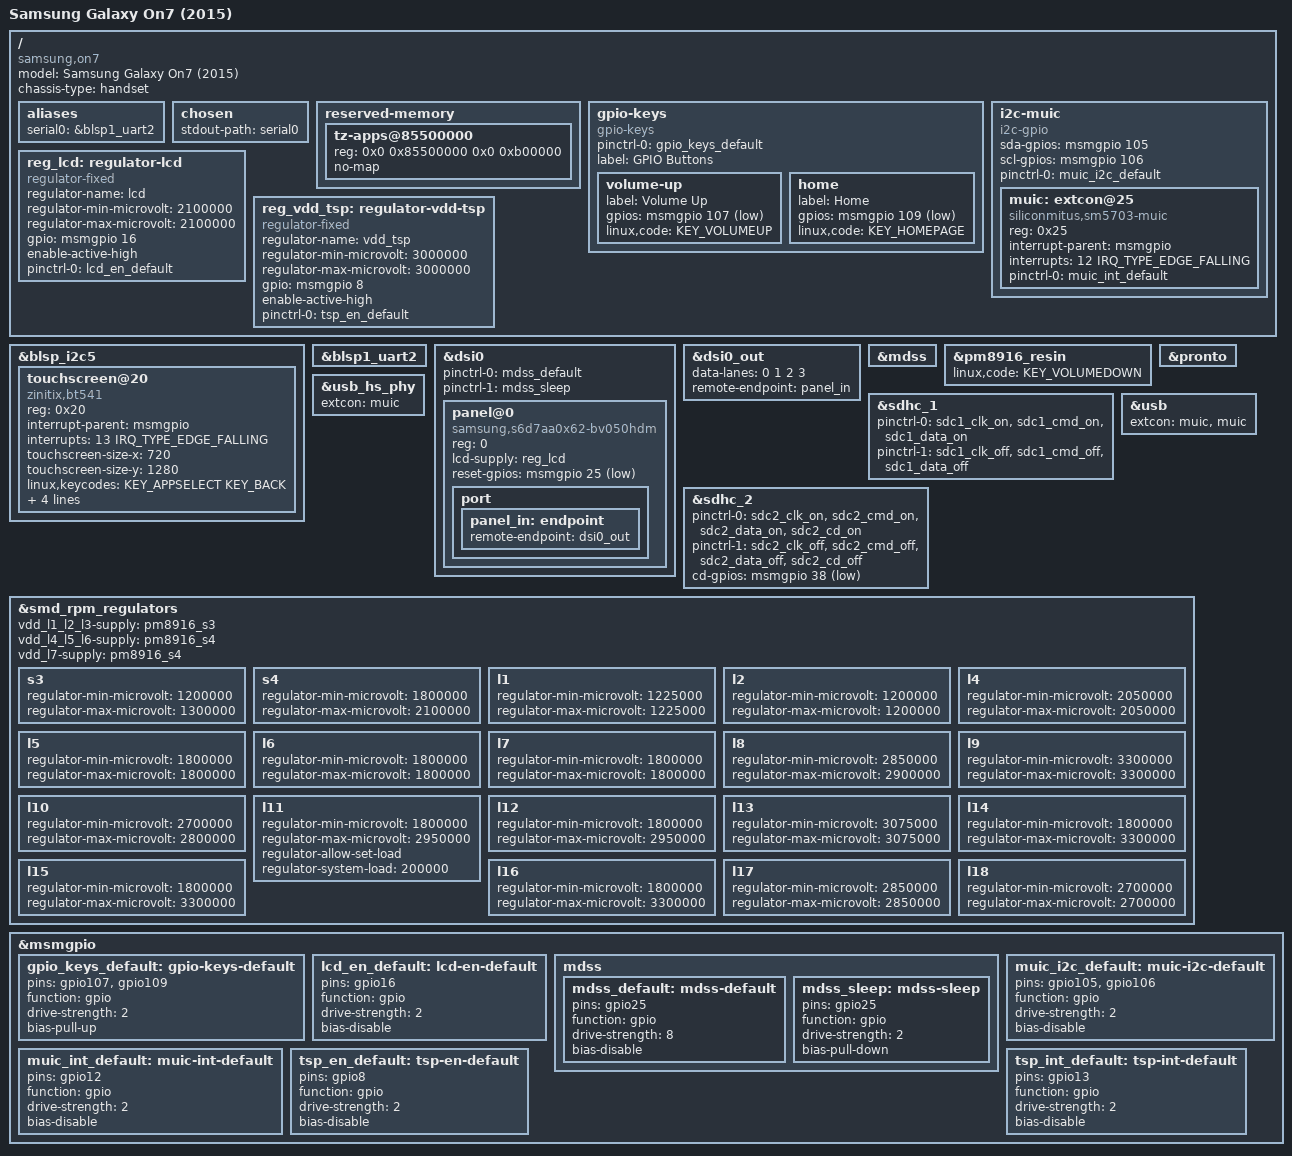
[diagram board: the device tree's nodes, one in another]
// SPDX-License-Identifier: GPL-2.0-only

/dts-v1/;

#include "msm8916-pm8916.dtsi"
#include <dt-bindings/gpio/gpio.h>
#include <dt-bindings/interrupt-controller/irq.h>

/ {
	model = "Samsung Galaxy On7 (2015)";
	compatible = "samsung,on7", "qcom,msm8916";
	chassis-type = "handset";

	aliases {
		serial0 = &blsp1_uart2;
	};

	chosen {
		stdout-path = "serial0";
	};

	reserved-memory {
		/* Additional memory used by Samsung firmware modifications */
		tz-apps@85500000 {
			reg = <0x0 0x85500000 0x0 0xb00000>;
			no-map;
		};
	};

	gpio-keys {
		compatible = "gpio-keys";

		pinctrl-names = "default";
		pinctrl-0 = <&gpio_keys_default>;

		label = "GPIO Buttons";

		volume-up {
			label = "Volume Up";
			gpios = <&msmgpio 107 GPIO_ACTIVE_LOW>;
			linux,code = <KEY_VOLUMEUP>;
		};

		home {
			label = "Home";
			gpios = <&msmgpio 109 GPIO_ACTIVE_LOW>;
			linux,code = <KEY_HOMEPAGE>;
		};
	};

	i2c-muic {
		compatible = "i2c-gpio";
		sda-gpios = <&msmgpio 105 (GPIO_ACTIVE_HIGH|GPIO_OPEN_DRAIN)>;
		scl-gpios = <&msmgpio 106 (GPIO_ACTIVE_HIGH|GPIO_OPEN_DRAIN)>;

		pinctrl-names = "default";
		pinctrl-0 = <&muic_i2c_default>;

		#address-cells = <1>;
		#size-cells = <0>;

		muic: extcon@25 {
			compatible = "siliconmitus,sm5703-muic";
			reg = <0x25>;

			interrupt-parent = <&msmgpio>;
			interrupts = <12 IRQ_TYPE_EDGE_FALLING>;

			pinctrl-names = "default";
			pinctrl-0 = <&muic_int_default>;
		};
	};

	reg_lcd: regulator-lcd {
		compatible = "regulator-fixed";
		regulator-name = "lcd";
		regulator-min-microvolt = <2100000>;
		regulator-max-microvolt = <2100000>;

		gpio = <&msmgpio 16 GPIO_ACTIVE_HIGH>;
		enable-active-high;

		pinctrl-names = "default";
		pinctrl-0 = <&lcd_en_default>;
	};

	reg_vdd_tsp: regulator-vdd-tsp {
		compatible = "regulator-fixed";
		regulator-name = "vdd_tsp";
		regulator-min-microvolt = <3000000>;
		regulator-max-microvolt = <3000000>;

		gpio = <&msmgpio 8 GPIO_ACTIVE_HIGH>;
		enable-active-high;

		pinctrl-names = "default";
		pinctrl-0 = <&tsp_en_default>;
	};
};

&blsp_i2c5 {
	status = "okay";

	touchscreen@20 {
		/* NOTE: Actually an ZT7548 that implements same interface */
		compatible = "zinitix,bt541";

		reg = <0x20>;
		interrupt-parent = <&msmgpio>;
		interrupts = <13 IRQ_TYPE_EDGE_FALLING>;

		touchscreen-size-x = <720>;
		touchscreen-size-y = <1280>;
		linux,keycodes = <KEY_APPSELECT KEY_BACK>;

		vdd-supply = <&reg_vdd_tsp>;
		vddo-supply = <&pm8916_l6>;
		zinitix,mode = <1>; //Will not work due to check in zinitix.c

		pinctrl-names = "default";
		pinctrl-0 = <&tsp_int_default>;
	};
};

&blsp1_uart2 {
	status = "okay";
};

&dsi0 {
		pinctrl-names = "default", "sleep";
		pinctrl-0 = <&mdss_default>;
		pinctrl-1 = <&mdss_sleep>;

        panel@0 {
                compatible = "samsung,s6d7aa0x62-bv050hdm";
                reg = <0>;

                lcd-supply = <&reg_lcd>;
                reset-gpios = <&msmgpio 25 GPIO_ACTIVE_LOW>;

                port {
                        panel_in: endpoint {
                                remote-endpoint = <&dsi0_out>;
                        };
                };
        };
};

&dsi0_out {
        data-lanes = <0 1 2 3>;
        remote-endpoint = <&panel_in>;
};

&mdss {
	status = "okay";
};

&pm8916_resin {
	status = "okay";
	linux,code = <KEY_VOLUMEDOWN>;
};

&pronto {
	status = "okay";
};

&sdhc_1 {
	status = "okay";

	pinctrl-names = "default", "sleep";
	pinctrl-0 = <&sdc1_clk_on &sdc1_cmd_on &sdc1_data_on>;
	pinctrl-1 = <&sdc1_clk_off &sdc1_cmd_off &sdc1_data_off>;
};

&sdhc_2 {
	status = "okay";

	pinctrl-names = "default", "sleep";
	pinctrl-0 = <&sdc2_clk_on &sdc2_cmd_on &sdc2_data_on &sdc2_cd_on>;
	pinctrl-1 = <&sdc2_clk_off &sdc2_cmd_off &sdc2_data_off &sdc2_cd_off>;

	cd-gpios = <&msmgpio 38 GPIO_ACTIVE_LOW>;
};

&usb {
	status = "okay";
	extcon = <&muic>, <&muic>;
};

&usb_hs_phy {
	extcon = <&muic>;
};

&smd_rpm_regulators {
	vdd_l1_l2_l3-supply = <&pm8916_s3>;
	vdd_l4_l5_l6-supply = <&pm8916_s4>;
	vdd_l7-supply = <&pm8916_s4>;

	s3 {
		regulator-min-microvolt = <1200000>;
		regulator-max-microvolt = <1300000>;
	};

	s4 {
		regulator-min-microvolt = <1800000>;
		regulator-max-microvolt = <2100000>;
	};

	l1 {
		regulator-min-microvolt = <1225000>;
		regulator-max-microvolt = <1225000>;
	};

	l2 {
		regulator-min-microvolt = <1200000>;
		regulator-max-microvolt = <1200000>;
	};

	l4 {
		regulator-min-microvolt = <2050000>;
		regulator-max-microvolt = <2050000>;
	};

	l5 {
		regulator-min-microvolt = <1800000>;
		regulator-max-microvolt = <1800000>;
	};

	l6 {
		regulator-min-microvolt = <1800000>;
		regulator-max-microvolt = <1800000>;
	};

	l7 {
		regulator-min-microvolt = <1800000>;
		regulator-max-microvolt = <1800000>;
	};

	l8 {
		regulator-min-microvolt = <2850000>;
		regulator-max-microvolt = <2900000>;
	};

	l9 {
		regulator-min-microvolt = <3300000>;
		regulator-max-microvolt = <3300000>;
	};

	l10 {
		regulator-min-microvolt = <2700000>;
		regulator-max-microvolt = <2800000>;
	};

	l11 {
		regulator-min-microvolt = <1800000>;
		regulator-max-microvolt = <2950000>;
		regulator-allow-set-load;
		regulator-system-load = <200000>;
	};

	l12 {
		regulator-min-microvolt = <1800000>;
		regulator-max-microvolt = <2950000>;
	};

	l13 {
		regulator-min-microvolt = <3075000>;
		regulator-max-microvolt = <3075000>;
	};

	l14 {
		regulator-min-microvolt = <1800000>;
		regulator-max-microvolt = <3300000>;
	};

	l15 {
		regulator-min-microvolt = <1800000>;
		regulator-max-microvolt = <3300000>;
	};

	l16 {
		regulator-min-microvolt = <1800000>;
		regulator-max-microvolt = <3300000>;
	};

	l17 {
		regulator-min-microvolt = <2850000>;
		regulator-max-microvolt = <2850000>;
	};

	l18 {
		regulator-min-microvolt = <2700000>;
		regulator-max-microvolt = <2700000>;
	};
};

&msmgpio {
	gpio_keys_default: gpio-keys-default {
		pins = "gpio107", "gpio109";
		function = "gpio";

		drive-strength = <2>;
		bias-pull-up;
	};

	lcd_en_default: lcd-en-default {
		pins = "gpio16";
		function = "gpio";

		drive-strength = <2>;
		bias-disable;
	};

	mdss {
		mdss_default: mdss-default {
			pins = "gpio25";
			function = "gpio";

			drive-strength = <8>;
			bias-disable;
		};
		mdss_sleep: mdss-sleep {
			pins = "gpio25";
			function = "gpio";

			drive-strength = <2>;
			bias-pull-down;
		};
	};

	muic_i2c_default: muic-i2c-default {
		pins = "gpio105", "gpio106";
		function = "gpio";

		drive-strength = <2>;
		bias-disable;
	};

	muic_int_default: muic-int-default {
		pins = "gpio12";
		function = "gpio";

		drive-strength = <2>;
		bias-disable;
	};

	tsp_en_default: tsp-en-default {
		pins = "gpio8";
		function = "gpio";

		drive-strength = <2>;
		bias-disable;
	};

	tsp_int_default: tsp-int-default {
		pins = "gpio13";
		function = "gpio";

		drive-strength = <2>;
		bias-disable;
	};
};
